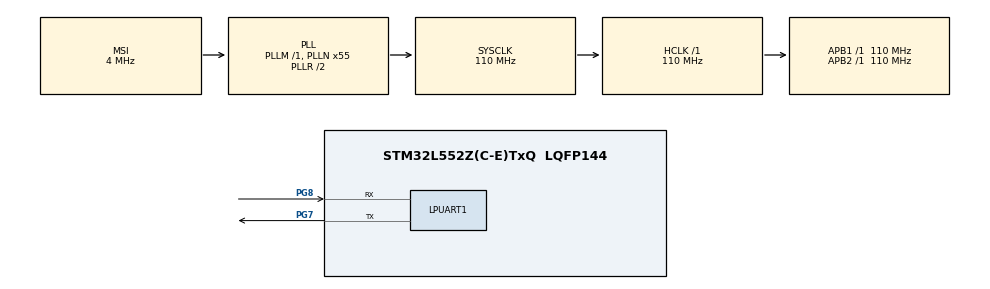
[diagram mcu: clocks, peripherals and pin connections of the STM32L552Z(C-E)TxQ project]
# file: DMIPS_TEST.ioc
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Mcu.Family=STM32L5
Mcu.Name=STM32L552Z(C-E)TxQ
Mcu.Package=LQFP144
NVIC.PriorityGroup=NVIC_PRIORITYGROUP_3
PG7.Mode=Asynchronous
PG7.Signal=LPUART1_TX
PG8.Mode=Asynchronous
PG8.Signal=LPUART1_RX
ProjectManager.HeapSize=0x200
ProjectManager.StackSize=0x400
ProjectManager.TargetToolchain=MDK-ARM V5.32
RCC.AHBFreq_Value=110000000
RCC.APB1Freq_Value=110000000
RCC.APB1TimFreq_Value=110000000
RCC.APB2Freq_Value=110000000
RCC.APB2TimFreq_Value=110000000
RCC.CortexFreq_Value=110000000
RCC.HCLKFreq_Value=110000000
RCC.HSE_VALUE=16000000
RCC.HSI48_VALUE=48000000
RCC.HSI_VALUE=16000000
RCC.LSE_VALUE=32768
RCC.MSI_VALUE=4000000
RCC.PLLN=55
RCC.SYSCLKFreq_VALUE=110000000
RCC.SYSCLKSource=RCC_SYSCLKSOURCE_PLLCLK
RCC.VCOOutputFreq_Value=220000000
TIM5.Channel-Output\ Compare1\ No\ Output=TIM_CHANNEL_1
VP_ICACHE_VS_ICACHE.Mode=DirectMappedCache
VP_PWR_VS_DBSignals.Mode=DisableDeadBatterySignals
VP_PWR_VS_SECSignals.Mode=Security/Privilege
VP_TIM5_VS_ClockSourceINT.Mode=Internal
VP_TIM5_VS_no_output1.Mode=Output Compare1 No Output
board=custom

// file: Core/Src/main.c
/* USER CODE BEGIN Header */
/**
  ******************************************************************************
  * @file           : main.c
  * @brief          : Main program body
  ******************************************************************************
  * @attention
  *
  * Copyright (c) 2024 STMicroelectronics.
  * All rights reserved.
  *
  * This software is licensed under terms that can be found in the LICENSE file
  * in the root directory of this software component.
  * If no LICENSE file comes with this software, it is provided AS-IS.
  *
  ******************************************************************************
  */
/* USER CODE END Header */
#include "main.h"

/* USER CODE BEGIN Includes */
#include "dhrystone.h"
/* USER CODE END Includes */

/* USER CODE BEGIN PD */
#define SYSTICK_LOAD 0xFFFFFF
#define SYSTICK_START 7
#define OVERFLOW_VAR 0xFFFFFFFF
/* USER CODE END PD */

UART_HandleTypeDef hlpuart1;

TIM_HandleTypeDef htim5;

/* USER CODE BEGIN PV */
uint8_t receive[15];
volatile uint64_t tmp1;
/* USER CODE END PV */
/* USER CODE BEGIN PM */
#if USE_DWT
		volatile unsigned int *DWT_CYCCNT   = (volatile unsigned int *)0xE0001004;
		volatile unsigned int *DWT_CONTROL  = (volatile unsigned int *)0xE0001000;
#endif

/* USER CODE END PV */

void SystemClock_Config(void);
static void MX_GPIO_Init(void);
static void MX_ICACHE_Init(void);
static void MX_LPUART1_UART_Init(void);
static void MX_TIM5_Init(void);

int main(void)
{

  /* MCU Configuration--------------------------------------------------------*/

  /* Reset of all peripherals, Initializes the Flash interface and the Systick. */
  HAL_Init();

  /* Configure the system clock */
  SystemClock_Config();

  /* Initialize all configured peripherals */
  MX_GPIO_Init();
  MX_ICACHE_Init();
  MX_LPUART1_UART_Init();
  MX_TIM5_Init();
  /* USER CODE BEGIN 2 */
	start_Test();
  /* USER CODE END 2 */

  /* Infinite loop */
  while (1)
  {

  }
}

void SystemClock_Config(void)
{
  RCC_OscInitTypeDef RCC_OscInitStruct = {0};
  RCC_ClkInitTypeDef RCC_ClkInitStruct = {0};

  /** Configure the main internal regulator output voltage
  */
  if (HAL_PWREx_ControlVoltageScaling(PWR_REGULATOR_VOLTAGE_SCALE0) != HAL_OK)
  {
    Error_Handler();
  }

  /** Initializes the RCC Oscillators according to the specified parameters
  * in the RCC_OscInitTypeDef structure.
  */
  RCC_OscInitStruct.OscillatorType = RCC_OSCILLATORTYPE_MSI;
  RCC_OscInitStruct.MSIState = RCC_MSI_ON;
  RCC_OscInitStruct.MSICalibrationValue = RCC_MSICALIBRATION_DEFAULT;
  RCC_OscInitStruct.MSIClockRange = RCC_MSIRANGE_6;
  RCC_OscInitStruct.PLL.PLLState = RCC_PLL_ON;
  RCC_OscInitStruct.PLL.PLLSource = RCC_PLLSOURCE_MSI;
  RCC_OscInitStruct.PLL.PLLM = 1;
  RCC_OscInitStruct.PLL.PLLN = 55;
  RCC_OscInitStruct.PLL.PLLP = RCC_PLLP_DIV7;
  RCC_OscInitStruct.PLL.PLLQ = RCC_PLLQ_DIV2;
  RCC_OscInitStruct.PLL.PLLR = RCC_PLLR_DIV2;
  if (HAL_RCC_OscConfig(&RCC_OscInitStruct) != HAL_OK)
  {
    Error_Handler();
  }

  /** Initializes the CPU, AHB and APB buses clocks
  */
  RCC_ClkInitStruct.ClockType = RCC_CLOCKTYPE_HCLK|RCC_CLOCKTYPE_SYSCLK
                              |RCC_CLOCKTYPE_PCLK1|RCC_CLOCKTYPE_PCLK2;
  RCC_ClkInitStruct.SYSCLKSource = RCC_SYSCLKSOURCE_PLLCLK;
  RCC_ClkInitStruct.AHBCLKDivider = RCC_SYSCLK_DIV1;
  RCC_ClkInitStruct.APB1CLKDivider = RCC_HCLK_DIV1;
  RCC_ClkInitStruct.APB2CLKDivider = RCC_HCLK_DIV1;

  if (HAL_RCC_ClockConfig(&RCC_ClkInitStruct, FLASH_LATENCY_5) != HAL_OK)
  {
    Error_Handler();
  }
}

static void MX_ICACHE_Init(void)
{

  /** Enable instruction cache in 1-way (direct mapped cache)
  */
  if (HAL_ICACHE_ConfigAssociativityMode(ICACHE_1WAY) != HAL_OK)
  {
    Error_Handler();
  }
  if (HAL_ICACHE_Enable() != HAL_OK)
  {
    Error_Handler();
  }

}

static void MX_LPUART1_UART_Init(void)
{

  hlpuart1.Instance = LPUART1;
  hlpuart1.Init.BaudRate = 115200;
  hlpuart1.Init.WordLength = UART_WORDLENGTH_8B;
  hlpuart1.Init.StopBits = UART_STOPBITS_1;
  hlpuart1.Init.Parity = UART_PARITY_NONE;
  hlpuart1.Init.Mode = UART_MODE_TX_RX;
  hlpuart1.Init.HwFlowCtl = UART_HWCONTROL_NONE;
  hlpuart1.Init.OneBitSampling = UART_ONE_BIT_SAMPLE_DISABLE;
  hlpuart1.Init.ClockPrescaler = UART_PRESCALER_DIV1;
  hlpuart1.AdvancedInit.AdvFeatureInit = UART_ADVFEATURE_NO_INIT;
  hlpuart1.FifoMode = UART_FIFOMODE_DISABLE;
  if (HAL_UART_Init(&hlpuart1) != HAL_OK)
  {
    Error_Handler();
  }
  if (HAL_UARTEx_SetTxFifoThreshold(&hlpuart1, UART_TXFIFO_THRESHOLD_1_8) != HAL_OK)
  {
    Error_Handler();
  }
  if (HAL_UARTEx_SetRxFifoThreshold(&hlpuart1, UART_RXFIFO_THRESHOLD_1_8) != HAL_OK)
  {
    Error_Handler();
  }
  if (HAL_UARTEx_DisableFifoMode(&hlpuart1) != HAL_OK)
  {
    Error_Handler();
  }

}

static void MX_TIM5_Init(void)
{

  TIM_ClockConfigTypeDef sClockSourceConfig = {0};
  TIM_MasterConfigTypeDef sMasterConfig = {0};
  TIM_OC_InitTypeDef sConfigOC = {0};

  htim5.Instance = TIM5;
  htim5.Init.Prescaler = 0;
  htim5.Init.CounterMode = TIM_COUNTERMODE_UP;
  htim5.Init.Period = 4294967295;
  htim5.Init.ClockDivision = TIM_CLOCKDIVISION_DIV1;
  htim5.Init.AutoReloadPreload = TIM_AUTORELOAD_PRELOAD_DISABLE;
  if (HAL_TIM_Base_Init(&htim5) != HAL_OK)
  {
    Error_Handler();
  }
  sClockSourceConfig.ClockSource = TIM_CLOCKSOURCE_INTERNAL;
  if (HAL_TIM_ConfigClockSource(&htim5, &sClockSourceConfig) != HAL_OK)
  {
    Error_Handler();
  }
  if (HAL_TIM_OC_Init(&htim5) != HAL_OK)
  {
    Error_Handler();
  }
  sMasterConfig.MasterOutputTrigger = TIM_TRGO_RESET;
  sMasterConfig.MasterSlaveMode = TIM_MASTERSLAVEMODE_DISABLE;
  if (HAL_TIMEx_MasterConfigSynchronization(&htim5, &sMasterConfig) != HAL_OK)
  {
    Error_Handler();
  }
  sConfigOC.OCMode = TIM_OCMODE_TIMING;
  sConfigOC.Pulse = 0;
  sConfigOC.OCPolarity = TIM_OCPOLARITY_HIGH;
  sConfigOC.OCFastMode = TIM_OCFAST_DISABLE;
  if (HAL_TIM_OC_ConfigChannel(&htim5, &sConfigOC, TIM_CHANNEL_1) != HAL_OK)
  {
    Error_Handler();
  }

}

static void MX_GPIO_Init(void)
{

  /* GPIO Ports Clock Enable */
  __HAL_RCC_GPIOG_CLK_ENABLE();
  HAL_PWREx_EnableVddIO2();

}

/* USER CODE BEGIN 4 */
void Serial_PutString(uint8_t *p_string)
{
  uint16_t length = 0;

  while (p_string[length] != '\0')
  {
    length++;
  }
  HAL_UART_Transmit(&hlpuart1, p_string, length, 0xFFFF);
}

void Serial_GetString()
{
	uint8_t i=0;
	do
	{
		HAL_UART_Receive(&hlpuart1, receive+i,1 , 0xFFFF);
		i++;
	}
	while(*(receive+i-1)!=13);
}

uint32_t strcpy_cust(char* strDest, char* strSrc)
{
	int32_t cnt=-1;

	do
	{
		cnt++;
		*(strDest+cnt)=*(strSrc+cnt);
	}
	while(*(strDest+cnt)!='\0');

	return ++cnt;
}

uint32_t strcmp_cust(char* str1, char* str2)
{
  int32_t ret = 0;

  while (!(ret = *(unsigned char *) str1 - *(unsigned char *) str2) && *str2) ++str1, ++str2;

  if (ret < 0)

    ret = -1;
  else if (ret > 0)

    ret = 1 ;

  return ret;
}

void memcpy_cust (char *d,char *s, uint32_t l)
{
        while (l--) *d++ = *s++;
}

uint32_t startTimer()
{
	#ifdef USE_DWT  //use debug watch timer
		*DWT_CONTROL|=DWT_CTRL_CYCCNTENA_Msk;
		*DWT_CYCCNT=NULL;
		return *DWT_CYCCNT;

	#elif USE_TIMER   //use timer
		HAL_TIM_Base_Start(&htim5);
		TIM5->CNT=NULL;
		return TIM5->CNT;

	#else  //use systick
	HAL_SuspendTick();
  SysTick->CTRL = NULL;

	uwTick = NULL;
  SysTick->VAL = NULL;
  SysTick->LOAD = SYSTICK_LOAD;
  SysTick->CTRL = SYSTICK_START;
	return NULL;
	#endif
}
uint32_t stopTimer()
{

	#if USE_DWT
			*DWT_CONTROL&=DWT_CTRL_CYCCNTENA_Msk;
			return *DWT_CYCCNT;

	#elif USE_TIMER
			HAL_TIM_Base_Stop(&htim5);
			return TIM5->CNT;
	#else
		 SysTick->CTRL = NULL;

    tmp1 = ((uint64_t)uwTick * SYSTICK_LOAD);
    tmp1 = tmp1 + (SYSTICK_LOAD - SysTick->VAL);
    if (tmp1 > OVERFLOW_VAR)
    {
      /* if end time = start time there is an overflow*/
      return NULL;
    }
    else
    {
      return (uint32_t)tmp1;
    }
	#endif
}

/* USER CODE END 4 */

void Error_Handler(void)
{
  __disable_irq();
  while (1)
  {
  }
}
